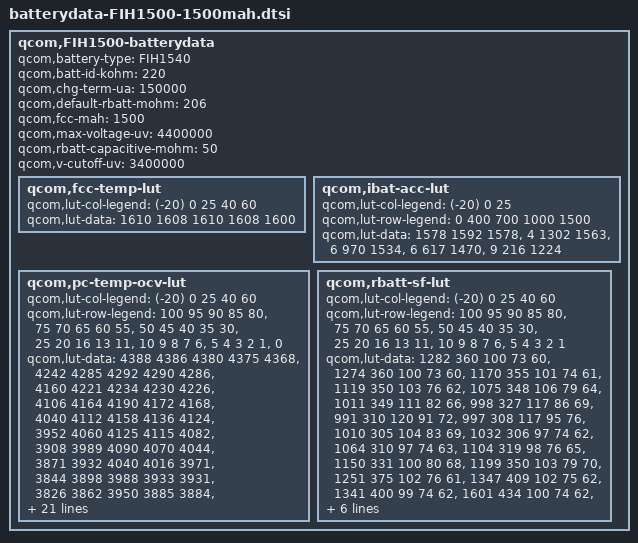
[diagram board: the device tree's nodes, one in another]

qcom,FIH1500-batterydata {
	qcom,battery-type = "FIH1540";
	qcom,batt-id-kohm = <220>;
	qcom,chg-term-ua = <150000>;
	qcom,default-rbatt-mohm = <206>;
	qcom,fcc-mah = <1500>;
	qcom,max-voltage-uv = <4400000>;
	qcom,rbatt-capacitive-mohm = <50>;
	qcom,v-cutoff-uv = <3400000>;

	qcom,fcc-temp-lut {
		qcom,lut-col-legend = <(-20) 0 25 40 60>;
		qcom,lut-data = <1610 1608 1610 1608 1600>;
	};

	qcom,ibat-acc-lut {
		qcom,lut-col-legend = <(-20) 0 25>;
		qcom,lut-row-legend = <0 400 700 1000 1500>;
		qcom,lut-data = <1578 1592 1578>,
				<4 1302 1563>,
				<6 970 1534>,
				<6 617 1470>,
				<9 216 1224>;
	};

	qcom,pc-temp-ocv-lut {
		qcom,lut-col-legend = <(-20) 0 25 40 60>;
		qcom,lut-row-legend = <100 95 90 85 80>,
					<75 70 65 60 55>,
					<50 45 40 35 30>,
					<25 20 16 13 11>,
					<10 9 8 7 6>,
					<5 4 3 2 1>,
					<0>;
		qcom,lut-data =
				/*-20  0    25   40   60*/
				<4388 4386 4380 4375 4368>,/*100*/
				<4242 4285 4292 4290 4286>,/*95*/
				<4160 4221 4234 4230 4226>,/*90*/
				<4106 4164 4190 4172 4168>,/*85*/
				<4040 4112 4158 4136 4124>,/*80*/
				<3952 4060 4125 4115 4082>,/*75*/
				<3908 3989 4090 4070 4044>,/*70*/
				<3871 3932 4040 4016 3971>,/*65*/
				<3844 3898 3988 3933 3931>,/*60*/
				<3826 3862 3950 3885 3884>,/*55*/
				<3812 3833 3925 3846 3846>,/*50*/
				<3800 3810 3880 3820 3820>,/*45*/
				<3786 3794 3840 3800 3800>,/*40*/
				<3772 3784 3800 3784 3784>,/*35*/
				<3758 3774 3784 3770 3769>,/*30*/
				<3741 3761 3761 3754 3740>,/*25*/
				<3724 3744 3743 3734 3720>,/*20*/
				<3708 3726 3722 3714 3701>,/*16*/
				<3692 3707 3702 3693 3680>,/*13*/
				<3678 3699 3690 3682 3671>,/*11*/
				<3668 3696 3688 3682 3670>,/*10*/
				<3658 3692 3687 3680 3669>,/*9*/
				<3646 3689 3685 3679 3668>,/*8*/
				<3630 3686 3683 3676 3665>,/*7*/
				<3610 3678 3677 3670 3656>,/*6*/
				<3584 3660 3656 3644 3630>,/*5*/
				<3548 3624 3612 3599 3584>,/*4*/
				<3501 3569 3554 3538 3523>,/*3*/
				<3422 3495 3462 3457 3439>,/*2*/
				<3274 3354 3322 3324 3306>,/*1*/
				<3004 3000 3000 3000 3000>;/*0*/
	};

	qcom,rbatt-sf-lut {
		qcom,lut-col-legend = <(-20) 0 25 40 60>;
		qcom,lut-row-legend = <100 95 90 85 80>,
					<75 70 65 60 55>,
					<50 45 40 35 30>,
					<25 20 16 13 11>,
					<10 9 8 7 6>,
					<5 4 3 2 1>;
		qcom,lut-data = <1282 360 100 73 60>,
				<1274 360 100 73 60>,
				<1170 355 101 74 61>,
				<1119 350 103 76 62>,
				<1075 348 106 79 64>,
				<1011 349 111 82 66>,
				<998 327 117 86 69>,
				<991 310 120 91 72>,
				<997 308 117 95 76>,
				<1010 305 104 83 69>,
				<1032 306 97 74 62>,
				<1064 310 97 74 63>,
				<1104 319 98 76 65>,
				<1150 331 100 80 68>,
				<1199 350 103 79 70>,
				<1251 375 102 76 61>,
				<1347 409 102 75 62>,
				<1341 400 99 74 62>,
				<1601 434 100 74 62>,
				<1837 468 101 73 60>,
				<1988 489 103 74 62>,
				<2167 515 106 77 65>,
				<2386 542 109 80 66>,
				<2676 577 114 83 67>,
				<3061 618 117 83 67>,
				<3584 659 117 80 65>,
				<4365 705 118 81 66>,
				<5571 775 126 84 68>,
				<7919 863 141 93 76>,
				<15839 1725 282 185 99>;
	};
};
/* TEST_DB_ID=TEST_ID_NOT_SET */
